# A31G33x register map
Vendor: VENDOR ABOV Semiconductor Co., Ltd.; Series: A31G33x; File version: 1.0
CPU: CM0+ r0p1, little endian, no MPU, no FPU, VTOR, 2 interrupt priority bits
Registers are 32-bit, read-only, no defined reset value unless marked. A register's access mark holds for its fields unless they carry their own. Offsets are from the block's base; [hi:lo] are bit positions.

## TS — Temperature Sensor
Base 0x40005F80
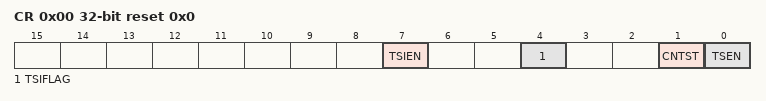
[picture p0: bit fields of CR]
0x00 CR rw reset 0x0 — Temperature Sensor Control Register
  [7] TSIEN — Temperature Sensor Interrupt Enable
    0=Disable interrupt; 1=Enable interrupt
  [4] TSIFLAG — Temperature Sensor Interrupt flag
    0=No request occurred; 1=Request occurred. This bit is cleared to '0' when write '1'.
  [1] CNTST — Counting Start
    0=Stop counting; 1=Start (Counting start after 'reload data to TS_ICNT and clear TS_OUTDR'.)
  [0] TSEN — Temperature Sensor Enable
    0=Disable temperature sensor; 1=Enable temperature sensor
0x04 IDR rw reset 0xFFFFF — Temperature Sensor Interval Data Register
  [19:0] IDATA — Temperature Sensor Interval Data
0x08 ICNTR reset 0xFFFF — Temperature Sensor Interval Counter Register
  [19:0] ICNT — Temperature Sensor Interval Counter
0x0C OUTDR reset 0x0 — Temperature Sensor Output Data Register
  [23:0] OUTDATA — Temperature Sensor Output Data

## CMPn — Comparator n
Base 0x52000000
Same registers: CMP0 0x40005600, CMP1 0x40005680
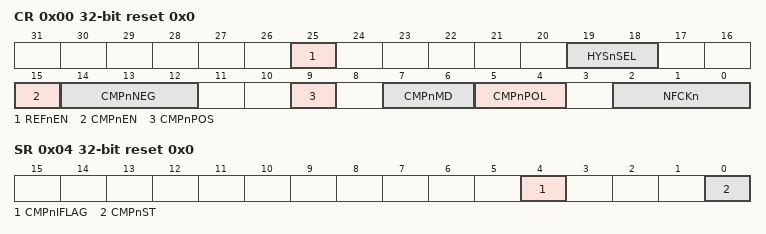
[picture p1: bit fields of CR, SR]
0x00 CR rw reset 0x0 — Comparator n Control Register
  [25] REFnEN — Comparator n Internal Reference Enable
    0=Disable internal reference; 1=Enable internal reference
  [19:18] HYSnSEL — Comparator n Hysteresis Selection
    0=Disable hysteresis; 1=Low (Enable low hysteresis.); 2=Medium (Enable medium hysteresis.); 3=High (Enable high hysteresis.)
  [15] CMPnEN — Comparator n Enable
    0=Disable comparator n operation; 1=Enable comparator n operation
  [14:12] CMPnNEG — Comparator n Negative Input Selection
    0=CPnN0 (Select external CPnN0 pin.); 1=CPnN1 (Select external CPnN1 pin.); 2=CPnN2 (Select external CPnN2 pin.); 3=IntRef_1p2V (Select internal reference 1.2V.); 4=IntRef_0p9V (Select internal reference 0.9V.); 5=IntRef_0p6V (Select internal reference 0.6V.); 6=IntRef_0p3V (Select internal reference 0.3V.)
  [9] CMPnPOS — Comparator n Positive Input Selection
    0=CPnP0 (Select external CPnP0 pin.); 1=CP0P0onCMP1 (Select CP0P0 signal on comparator 1 (Reserved on comparator 0))
  [7:6] CMPnMD — Comparator n Mode Selection
    0=Ultra low-power mode; 1=Low (Low-power mode); 2=Medium power mode; 3=High speed mode
  [5:4] CMPnPOL — Comparator n Interrupt Polarity Selection
    0=No interrupt at any edge; 1=FallingEdge (Interrupt on falling edge); 2=RisingEdge (Interrupt on rising edge); 3=BothEdge (Interrupt on both of falling and rising edge)
  [2:0] NFCKn — Comparator n Noise Filter Sampling Clock Selection
    0=PCLK1; 1=PCLK2; 2=PCLK4; 3=PCLK8; 4=PCLK16; 5=PCLK32; 6=PCLK64
0x04 SR rw reset 0x0 — Comparator n Status Register
  [4] CMPnIFLAG — Comparator n Interrupt Flag
    0=No request occurred; 1=Request occurred. This bit is cleared to '0' when write '1'.
  [0] CMPnST ro — Comparator n Output Status
    0=Low (Comparator n output is low.); 1=High (Comparator n output is high.)

## WDT — Watch-Dog Timer
Base 0x40001A00
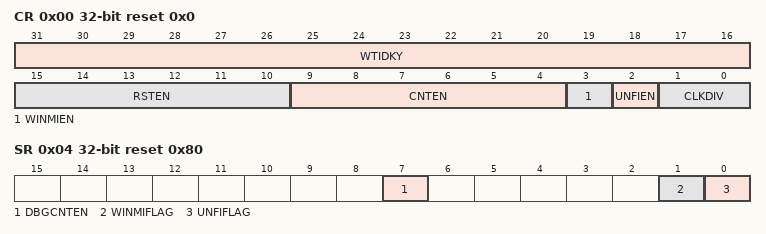
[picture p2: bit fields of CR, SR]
0x00 CR rw reset 0x0 — Watch-Dog Timer Control Register
  [31:16] WTIDKY wo — Write Identification Key (0x5a69)
    0x5A69=Value (Key Value (0x5a69))
  [15:10] RSTEN — Watch-Dog Timer Reset Enable
    37=Disable Watch-Dog Timer reset. (0x25); 0=Enable Watch-Dog Timer reset
  [9:4] CNTEN — Watch-Dog Timer Counter Enable
    26=Disable Watch-Dog Timer counter. (0x1a); 0=Enable Watch-Dog Timer counter
  [3] WINMIEN — Watch-Dog Timer Window Match Interrupt Enable
    0=Disable window data match interrupt; 1=Enable window data match interrupt
  [2] UNFIEN — Watch-Dog Timer Underflow Interrupt Enable
    0=Disable Watch-Dog Timer underflow interrupt; 1=Enable Watch-Dog Timer underflow interrupt
  [1:0] CLKDIV — Watch-Dog Timer Clock Divider
    0=fWDT4; 1=fWDT16; 2=fWDT64; 3=fWDT256
0x04 SR rw reset 0x80 — Watch-Dog Timer Status Register
  [7] DBGCNTEN — Watch-Dog Timer Counter Enable When the core is halted in debug mode
    0=Run (The Watch-Dog Timer counter continues even if the core is halted); 1=Stop (The Watch-Dog Timer counter is stopped when the core is halted)
  [1] WINMIFLAG — Watch-Dog Timer Window Match Interrupt Flag
    0=No request occurred; 1=Request occurred
  [0] UNFIFLAG — Watch-Dog Timer Underflow Interrupt Flag
    0=No request occurred; 1=Request occurred
0x08 DR rw reset 0xFFF — Watch-Dog Timer Data Register
  [23:0] DATA — Watch-Dog Timer Data
0x0C CNT reset 0xFFF — Watch-Dog Timer Counter Register
  [23:0] CNT — Watch-Dog Timer Counter
0x10 WINDR rw reset 0x1FFF — Watch-Dog Timer Window Data Register
  [23:0] WDATA — Watch-Dog Timer Window Data
0x14 CNTR wo reset 0x0 — Watch-Dog Timer Counter Reload Register
  [7:0] CNTR — Watch-Dog Timer Counter Reload
    106=Reload the WDTDR value to Watch-Dog Timer counter and re-start; 0=NoEffect
